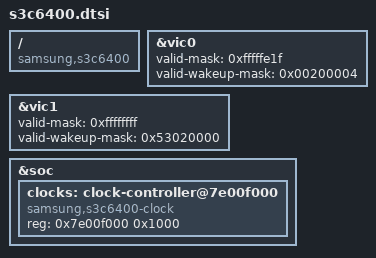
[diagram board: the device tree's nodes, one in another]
#include "s3c64xx.dtsi"
/ {
	compatible = "samsung,s3c6400";
};
&vic0 {
	valid-mask = <0xfffffe1f>;
	valid-wakeup-mask = <0x00200004>;
};
&vic1 {
	valid-mask = <0xffffffff>;
	valid-wakeup-mask = <0x53020000>;
};
&soc {
	clocks: clock-controller@7e00f000 {
		compatible = "samsung,s3c6400-clock";
		reg = <0x7e00f000 0x1000>;
		#clock-cells = <1>;
	};
};
